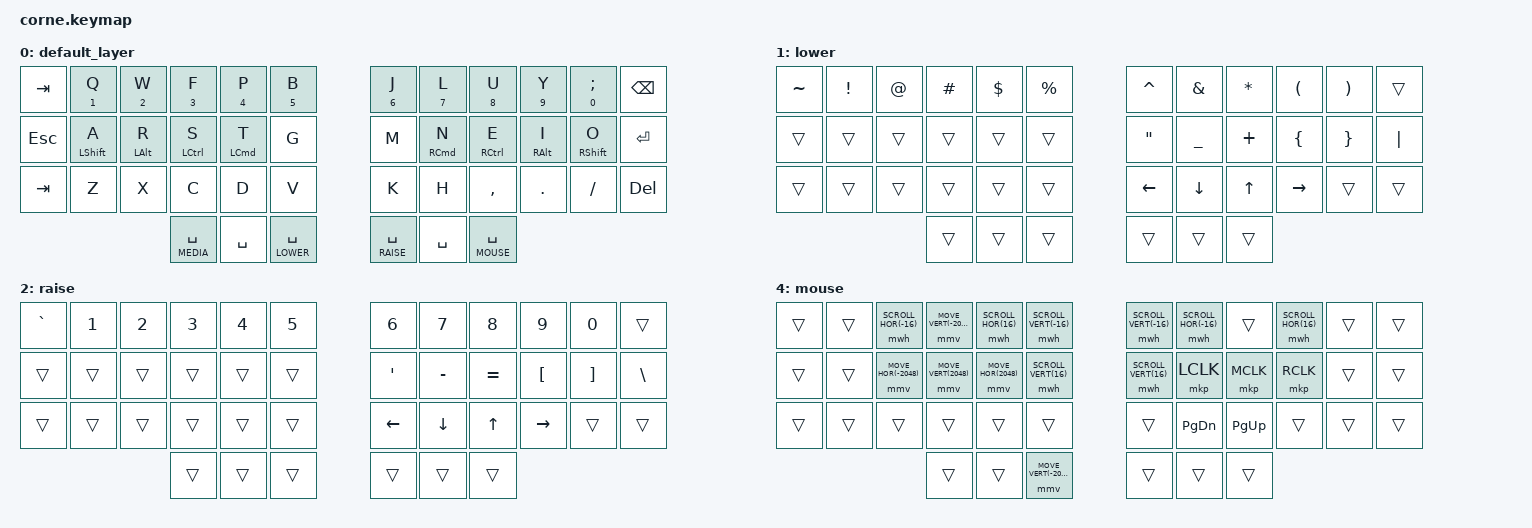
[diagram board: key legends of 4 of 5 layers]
/*
 * Copyright (c) 2020 The ZMK Contributors
 *
 * SPDX-License-Identifier: MIT
 */

#include <behaviors.dtsi>
#include <dt-bindings/zmk/bt.h>
#include <dt-bindings/zmk/ext_power.h>
#include <dt-bindings/zmk/keys.h>
#include <dt-bindings/zmk/mouse.h>
#include <dt-bindings/zmk/rgb.h>

#define BASE 0
#define LOWER 1
#define RAISE 2
#define MEDIA 3
#define MOUSE 4

&mt {
    flavor = "tap-preferred";
    tapping_term_ms = <200>;
};

&mmv {
     time-to-max-speed-ms = <256>;
     acceleration-exponent = <3>;
};

&mwh {
     time-to-max-speed-ms = <48>;
     acceleration-exponent = <4>;
};

/ {
        behaviors {
            hm: homerow_mods {
                compatible = "zmk,behavior-hold-tap";
                label = "HOMEROW_MODS";
                #binding-cells = <2>;
                tapping-term-ms = <200>;
                quick_tap_ms = <0>;
                flavor = "tap-preferred";
                bindings = <&kp>, <&kp>;
            };
            bl: layertap {
                compatible = "zmk,behavior-hold-tap";
                label = "LAYERTAP";
                #binding-cells = <2>;
                tapping-term-ms = <150>;
                quick_tap_ms = <0>;
                flavor = "tap-preferred";
                bindings = <&lt>, <&kp>;
            };
        };
        keymap {
                compatible = "zmk,keymap";

                default_layer {
                        bindings = <
   &kp TAB    &mt N1 Q     &mt N2 W         &mt N3 F     &mt N4 P         &mt N5 B      &mt N6 J   &mt N7 L         &mt N8 U     &mt N9 Y      &mt N0 SEMI    &kp BSPC
   &kp ESC    &hm LSHFT A  &hm LALT R       &hm LCTRL S  &hm LCMD T       &kp G         &kp M      &hm RCMD N       &hm RCTRL E  &hm RALT I    &hm RSHFT O    &kp ENTER
   &kp TAB    &kp Z        &kp X            &kp C        &kp D            &kp V         &kp K      &kp H            &kp COMMA    &kp DOT       &kp FSLH       &kp DEL
                           &lt MEDIA SPACE  &kp SPACE    &lt LOWER SPACE                           &lt RAISE SPACE  &kp SPACE    &lt MOUSE SPACE
                        >;
                };
                lower {
                        bindings = <
   &kp TILDE  &kp EXCL     &kp AT       &kp HASH     &kp DOLLAR   &kp PERCENT  &kp CARET  &kp AMPS     &kp STAR        &kp LPAR       &kp RPAR       &trans
   &trans     &trans       &trans       &trans       &trans       &trans       &kp DQT    &kp UNDER    &kp PLUS        &kp LBRC       &kp RBRC       &kp PIPE
   &trans     &trans       &trans       &trans       &trans       &trans       &kp LEFT   &kp DOWN     &kp UP          &kp RIGHT      &trans         &trans
                           &trans       &trans       &trans                               &trans       &trans          &trans
                        >;
                };
                raise {
                        bindings = <
   &kp GRAVE  &kp N1       &kp N2       &kp N3       &kp N4       &kp N5      &kp N6     &kp N7       &kp N8          &kp N9         &kp N0         &trans
   &trans     &trans       &trans       &trans       &trans       &trans      &kp SQT    &kp MINUS    &kp EQUAL       &kp LBKT       &kp RBKT       &kp BSLH
   &trans     &trans       &trans       &trans       &trans       &trans      &kp LEFT   &kp DOWN     &kp UP          &kp RIGHT      &trans         &trans
                           &trans       &trans       &trans                              &trans       &trans          &trans
                        >;
                };
                media {
                        bindings = <
   &ext_power EP_OFF  &ext_power EP_ON   &kp LC(LS(TAB))           &kp LG(TAB)             &kp LC(TAB)                &trans  &kp C_MUTE  &kp C_VOL_DN &kp C_VOL_UP  &kp C_PP   &kp C_PREV  &kp C_NEXT
   &trans             &trans             &kp LC(LS(LA(LG(LEFT))))  &kp LC(LS(LA(LG(UP))))  &kp LC(LS(LA(LG(RIGHT))))  &trans  &trans      &trans       &trans        &trans     &trans      &trans
   &trans             &trans             &trans                    &trans                  &trans                     &trans  &trans      &kp PG_DN    &kp PG_UP     &trans     &trans      &trans
                                         &trans                    &trans                  &trans                                         &kp RALT     &kp RCMD      &trans
                        >;
                };
                mouse {
                        bindings = <
   &trans     &trans       &mwh SCROLL_HOR(-16)  &mmv MOVE_VERT(-2048)  &mwh SCROLL_HOR(16)    &mwh SCROLL_VERT(-16) &mwh SCROLL_VERT(-16) &mwh SCROLL_HOR(-16)  &trans     &mwh SCROLL_HOR(16)  &trans  &trans
   &trans     &trans       &mmv MOVE_HOR(-2048)  &mmv MOVE_VERT(2048)   &mmv MOVE_HOR(2048)    &mwh SCROLL_VERT(16)  &mwh SCROLL_VERT(16)  &mkp LCLK             &mkp MCLK  &mkp RCLK            &trans  &trans
   &trans     &trans       &trans                &trans                 &trans                 &trans                &trans                &kp PG_DN             &kp PG_UP  &trans               &trans  &trans
                           &trans                &trans                 &mmv MOVE_VERT(-2048)                                              &trans                &trans     &trans
                        >;
                };
        };
};
